# MLDR187 register map
File version: 1.4
CPU: MDR32F02, little endian
Registers are 32-bit, read-write, no defined reset value unless marked. A register's access mark holds for its fields unless they carry their own. Offsets are from the block's base; [hi:lo] are bit positions; {n}, {i} and the like mark numbered series.

## I2C — I2C description
Base 0x40030000
0x00 PRL — PRL description
  [7:0] PR — PR description
0x04 PRH — PRH description
  [7:0] PR — PR description
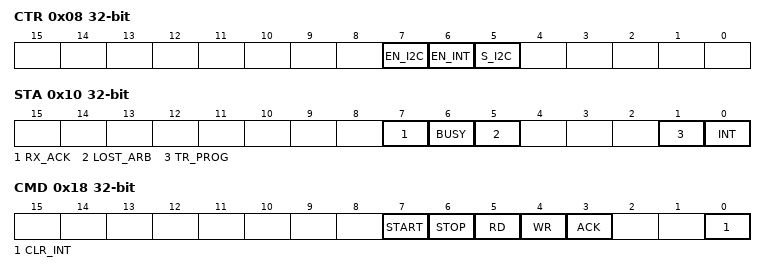
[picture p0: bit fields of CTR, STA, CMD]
0x08 CTR — CTR description
  [7] EN_I2C — EN_I2C description
  [6] EN_INT — EN_INT description
  [5] S_I2C — S_I2C description
0x0C RXD — RXD description
  [7:0] RXD
0x10 STA — STA description
  [7] RX_ACK — RX_ACK description
  [6] BUSY — BUSY description
  [5] LOST_ARB — LOST_ARB description
  [1] TR_PROG — TR_PROG description
  [0] INT — INT description
0x14 TXD — TXD description
  [7:0] TXD
0x18 CMD — CMD description
  [7] START — START description
  [6] STOP — STOP description
  [5] RD — RD description
  [4] WR — WR description
  [3] ACK — ACK description
  [0] CLR_INT — CLR_INT description

## CRC — CRC description
Base 0x40098000
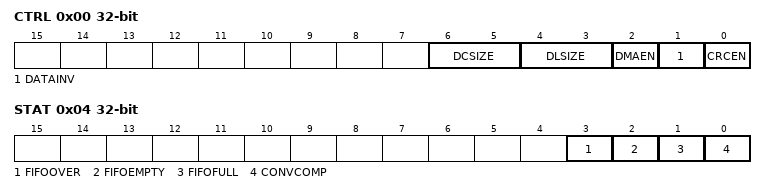
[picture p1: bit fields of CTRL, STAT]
0x00 CTRL — CTRL description
  [6:5] DCSIZE — DCSIZE description
  [4:3] DLSIZE — DLSIZE description
  [2] DMAEN — DMAEN description
  [1] DATAINV — DATAINV description
  [0] CRCEN — CRCEN description
0x04 STAT — STAT description
  [3] FIFOOVER — FIFOOVER description
  [2] FIFOEMPTY — FIFOEMPTY description
  [1] FIFOFULL — FIFOFULL description
  [0] CONVCOMP — CONVCOMP description
0x08 DATAI wo — DATAI description
  [31:0] DATA_IN — DATA_IN description
0x0C VAL — VAL description
  [15:0] CRCOUT — CRCOUT description
0x10 POL — POL description
  [16:0] CRC_POL — CRC_POL description

## EEPROM_CNTRL — EEPROM_CNTRL description
Base 0x40018000
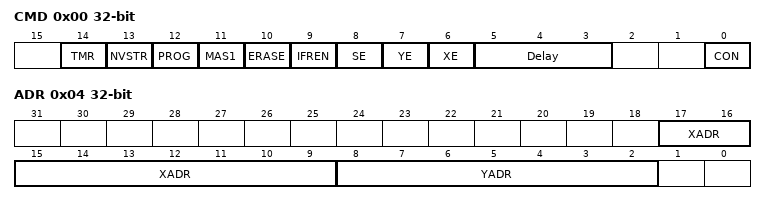
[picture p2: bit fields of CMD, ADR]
0x00 CMD — Registr upravlenija
  [14] TMR — Bit perevoda pamjat' v testovyj rezhim
  [13] NVSTR — Operacii zapisi ili stiranija
  [12] PROG — Bit programirovanija pamjati pri dostupe v pamjat'
  [11] MAS1 — Bit stiranija pamjati pri dostupe v pamjat'
  [10] ERASE — Bit stiranija pamjati pri dostupe v pamjat'
  [9] IFREN — Bit vybora tipa pamjati pri dostupe v pamjat'
  [8] SE — Bit razreshenija mladshej chasti adresa pri dostupe v pamjat' so storony registrov.
  [7] YE — Bit razreshenija starshej chasti adresa pri dostupe v pamjat' so storony registrov.
  [6] XE — Bit razreshenija dostupa k bankam pamjati
  [5:3] Delay — Zaderzhka pamjati programm pri chtenii v ciklah (v rabochem rezhime)
  [0] CON — Perekljuchenie kontrollera pamjati EEPROM na registrovoe upravlenie
0x04 ADR — ADR description
  [17:9] XADR — XADR[8:0] = page[5:0], row[2:0]
  [8:2] YADR — YADR[6:0] = col[6:0]
0x08 DI — Dannye dlja zapisi v EERPOM
0x0C DO — Dannye, schitannye iz EERPOM
0x10 KEY — 0x8AAA5551

## ADC — ADC description
Base 0x40040000
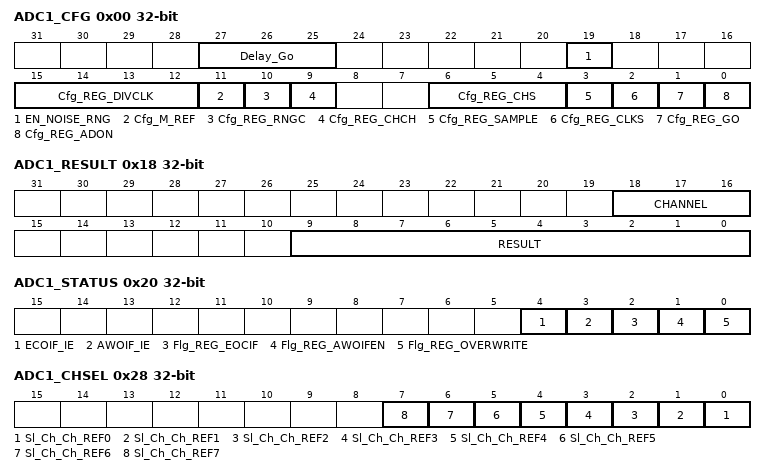
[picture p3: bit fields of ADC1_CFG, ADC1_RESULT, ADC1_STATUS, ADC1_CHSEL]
0x00 ADC1_CFG — ADC1_CFG description
  [27:25] Delay_Go — Delay_Go description
  [19] EN_NOISE_RNG — EN_NOISE_RNG description
  [15:12] Cfg_REG_DIVCLK — Cfg_REG_DIVCLK description
  [11] Cfg_M_REF — Cfg_M_REF description
  [10] Cfg_REG_RNGC — Cfg_REG_RNGC description
  [9] Cfg_REG_CHCH — Cfg_REG_CHCH description
  [6:4] Cfg_REG_CHS — Cfg_REG_CHS description
  [3] Cfg_REG_SAMPLE — Cfg_REG_SAMPLE description
  [2] Cfg_REG_CLKS — Cfg_REG_CLKS description
  [1] Cfg_REG_GO — Cfg_REG_GO description
  [0] Cfg_REG_ADON — Cfg_REG_ADON description
0x08 ADC1_H_LEVEL — ADC1_H_LEVEL description
  [9:0] REG_H_LEVEL — REG_H_LEVEL description
0x10 ADC1_L_LEVEL — ADC1_L_LEVEL description
  [9:0] REG_L_LEVEL — REG_L_LEVEL description
0x18 ADC1_RESULT — ADC1_RESULT description
  [18:16] CHANNEL — CHANNEL description
  [9:0] RESULT — RESULT description
0x20 ADC1_STATUS — ADC1_STATUS description
  [4] ECOIF_IE — ECOIF_IE description
  [3] AWOIF_IE — AWOIF_IE description
  [2] Flg_REG_EOCIF — Flg_REG_EOCIF description
  [1] Flg_REG_AWOIFEN — Flg_REG_AWOIFEN description
  [0] Flg_REG_OVERWRITE — Flg_REG_OVERWRITE description
0x28 ADC1_CHSEL — ADC1_CHSEL description
  [n] Sl_Ch_Ch_REF{n} (n=0..7) — Sl_Ch_Ch_REF{n} description
0x30 ADC1_TRIM — ADC1_TRIM description
  [5:1] BG_TRIM — BG_TRIM description
